# MIK32 register map
Vendor: Mikron; Series: MIK32; File version: 1.0
Registers are 32-bit, read-write, reset 0x0 unless marked. A register's access mark holds for its fields unless they carry their own. Offsets are from the block's base; [hi:lo] are bit positions; {n}, {i} and the like mark numbered series; 'fields as' and 'values as' point back to an identical list.

## TIMER32_0 — регистры модуля таймера_0
Base 0x00050800
0x00 TIM0_VALUE ro
  [31:0] TIM_VAL — текущее значение счетчика
0x04 TIM0_TOP reset 0xFFFFFFFF — максимальное значение счетной последовательности
  [31:0] TIM_TOP — максимальное значение счетчика (ограничивает счетную последоваельность сверху)
0x08 TIM0_PRESCALE — значение делителя
  [31:0] TIM_PRESCALE — Значение предварительного делителя. Предделитель вырабатывает тактовый сигнал для счета, частота которого в (TIM_PRESCALE + 1) раз меньше входной. Диапазон значений от 0 до (232 - 1)
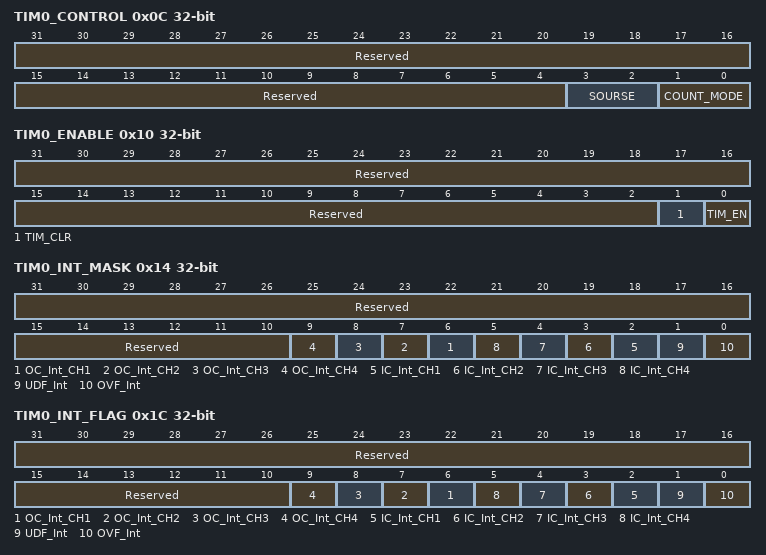
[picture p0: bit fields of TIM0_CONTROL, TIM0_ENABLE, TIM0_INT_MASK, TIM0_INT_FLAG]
0x0C TIM0_CONTROL reset not defined — Конфигурационный регистр основного таймера
  [31:4] Reserved — Зарезервировано
  [3:2] SOURSE — Выбор источника тактового сигнала для счета
    0=TIM1 (Вход модуля TIM1); 2=TIM2 (Вход модуля TIM2); 3=TIM3 (Выход предделителя)
  [1:0] COUNT_MODE — Режим счёта таймера
    0=Direct (Прямой режим); 1=Reverse (Обратный режим); 2=Bidirectional (Двунаправленный режим)
0x10 TIM0_ENABLE — Регистр включения таймера
  [31:2] Reserved — Зарезервировано
  [1] TIM_CLR write-once — Сброс (обнуление) текущего значения счетчика при записи «1»
  [0] TIM_EN — Запуск/остановка работы счетчика
    0=Disable (Счетчик выключен); 1=Enable (Счетчик работает)
0x14 TIM0_INT_MASK — Регистр маски прерываний
  [31:10] Reserved — Зарезервировано
  [n+5] OC_Int_CH{n} (n=1..4) — Маска прерывания совпадения {n} канала таймера
  [n+1] IC_Int_CH{n} (n=1..4) — Маска прерывания захвата {n} канала таймера
  [1] UDF_Int — Маска прерывания опустошения счетчика
  [0] OVF_Int — Маска прерывания по переполнению счетчика
0x18 TIM0_INT_CLEAR reset 0xFFFFFFFF — Регистр сброса флагов прерываний
0x1C TIM0_INT_FLAG ro — Регистр флагов прерываний
  [31:10] Reserved — Зарезервировано
  [n+5] OC_Int_CH{n} (n=1..4) — Статус прерывания совпадения {n} канала таймера
  [n+1] IC_Int_CH{n} (n=1..4) — Статус прерывания захвата {n} канала таймера
  [1] UDF_Int — Статус прерывания опустошения счетчика
  [0] OVF_Int — Статус прерывания по переполнению счетчика
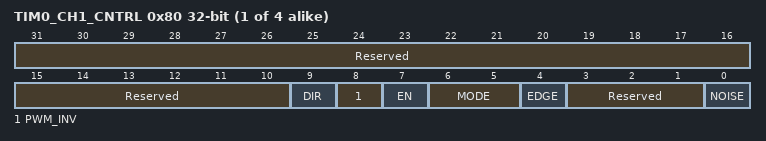
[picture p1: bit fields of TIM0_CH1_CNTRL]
{0x70+0x10*i} TIM0_CH{i}_CNTRL (i=1..4) — Конфигурационный регистр {i} канала
  [31:10] Reserved — Зарезервировано
  [9] DIR ro — Направление передачи данных. Устанавливается автоматически в зависимости от режима работы (1 - выход, 0 - вход)
    1=Output (Выход); 0=Input (Вход)
  [8] PWM_INV — Тип вывода в режиме ШИМ инвертирование
    0=Direct (Прямой (не инвертированный) выход); 1=Inverted (Инвертированный выход)
  [7] EN — Включение/выключение канала
  [6:5] MODE — Режим работы канала
    0=Reserved (Зарезервировано); 1=Compare (Режим сравнения (для timer0)); 2=Capture (Режим захвата(для timer0)); 3=PWM (ШИМ)
  [4] EDGE — Режим сигнала захвата
    0=Front (фронт); 1=Back (срез)
  [3:1] Reserved — Зарезервировано
  [0] NOISE — Управление фильтрацией входных помех на входе ic_port: 0 – фильтрация выклю-чена; 1 – фильтрация выклю-чена
    0=Enable (Фильтрация выключена); 1=Disable (Фильтрация включена)
{0x74+0x10*i} TIM0_CH{i}_OCR (i=1..4) — Значение сравнения {i} канала
  [31:0] OCR — Значение таймера в режиме сравнения
{0x78+0x10*i} TIM0_CH{i}_ICR (i=1..4) — Значение захвата {i} канала
  [31:0] ICR — Значение таймера в режиме захвата

## PVD_VCC — Управление монитором напряжения VCC
Base 0x00051800
0x00 DPF_VALUE reset 0x5DC — Настройка цифрового фильтра
  [31:14] Reserved — Зарезервировано
  [15:0] DPF — Коэффициент, определяющий длительность отфильтровываемых импульсов (на системной частоте)
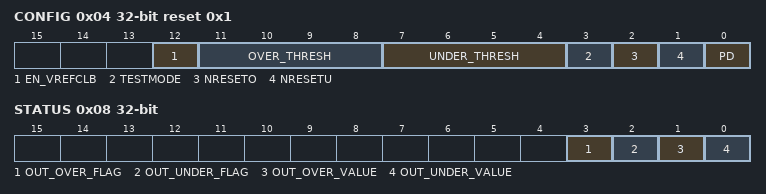
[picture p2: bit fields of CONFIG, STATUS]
0x04 CONFIG reset 0x1 — Регистр настроек
  [12] EN_VREFCLB — Использование в качестве опорного источника напряжения каллибруемый ОИН
  [11:8] OVER_THRESH — Верхний порог срабатывания монитора
  [7:4] UNDER_THRESH — Нижний порог срабатывания монитора
  [3] TESTMODE — Переход в тестовый режим
  [2] NRESETO — Отключение (сброс) детектирования вехнего порога
    0=Reset (Детектирование не выполняется, схема в состоянии сброса); 1=Normal (Нормальная работа)
  [1] NRESETU — Отключение (сброс) детектирования нижнего порога
    values as NRESETO
  [0] PD — Управление питанием монитора
    0=Enable (Монитор включен); 1=Disable (Монитор выключен)
0x08 STATUS ro — Регистр статуса
  [3] OUT_OVER_FLAG — Текущее состояние линии монитора верхнего порога с учетом цифровой фильтрации
  [2] OUT_UNDER_FLAG — Текущее состояние линии монитора нижнего порога с учетом цифровой фильтрации
  [1] OUT_OVER_VALUE — Текущее состояние линии монитора верхнего порога без цифровой фильтрации
  [0] OUT_UNDER_VALUE — Текущее состояние линии монитора нижнего порога без цифровой фильтрации

## PVD_AVCC — Управление монитором напряжения AVCC
Base 0x00085010
Registers as PVD_VCC; these are added or differ:
0x00 DPF_VALUE reset 0x5DC — Настройка цифрового фильтра
  [15:0] DPF — Коэффициент, определяющий длительность отфильтровываемых импульсов (на системной частоте)
